# MSPM0G321X register map
Vendor: Texas Instruments; File version: Revised: 2025-10-06 10:58:04
CPU: CM0 r0p1, little endian, MPU, no FPU, 3 interrupt priority bits
Registers are 32-bit, read-write, reset 0x0 unless marked. A register's access mark holds for its fields unless they carry their own. Offsets are from the block's base; [hi:lo] are bit positions; lines under a group give offsets from that group; {n}, {i} and the like mark numbered series; 'fields as' and 'values as' point back to an identical list.

## SPG0 — PERIPHERALREGION
Base 0x40A9F000
{0x1120+4i} SPG0_UNICOMM_LPBK[{i}] (i=0..0) group
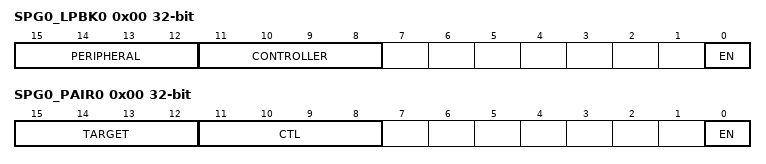
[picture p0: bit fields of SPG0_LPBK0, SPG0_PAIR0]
  0x00 SPG0_LPBK0 — Loopback between SPG instances User has to ensure that the SPGs looped back have the same underlying IP instantiated; i.e. both UART, both SPI, both I2C, etc.,
    [15:12] PERIPHERAL — Select SPG peripheral for loopback. Signals invovled in loopback based on interface chosen 1. SPI : CS, SCLK, SDI, SDO 2. I2C : SCL, SDA 3. UART : TX, RX
      {v}=SPG{v+1} (SPG responder select for loopback.) (v=0..15)
    [11:8] CONTROLLER — Select SPG controller for loopback. Signals invovled in loopback based on interface chosen 1. SPI : CS, SCLK, SDI, SDO 2. I2C : SCL, SDA 3. UART : TX, RX
      {v}=SPG{v+1} (SPG commander select for loopback.) (v=0..15)
    [0] EN — Loopback enable
      0=DISABLE (Does not select this clock as a source); 1=ENABLE (Select this clock as a source)
{0x11C0+4i} SPG0_I2C_PAIR[{i}] (i=0..0) group
  0x00 SPG0_PAIR0 — Pairing of I2C for MULTI-MASTER/SMBUS applications
    [15:12] TARGET — UNICOMM instance for loopback. This instance will be treated as the target
      {v}=SPG{v+1} (SPG responder select for loopback.) (v=0..15)
    [11:8] CTL — UNICOMM instance for loopback. This instance will be treated as the controller.
      {v}=SPG{v+1} (SPG commander select for loopback.) (v=0..15)
    [0] EN — Enable
      values as SPG0_UNICOMM_LPBK[0].SPG0_LPBK0.EN

## IOMUX — PERIPHERALREGION
Base 0x40428000
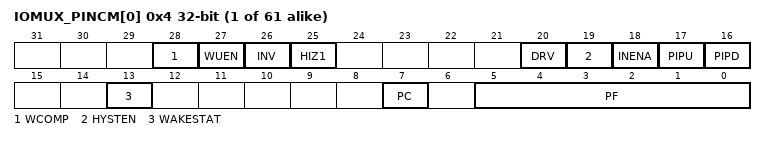
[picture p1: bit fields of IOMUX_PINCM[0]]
{0x4+4i} IOMUX_PINCM[{i}] (i=0..60) — Pin Control Management Register in SECCFG region
  [28] WCOMP — Wakeup Compare Value bit
    0=MATCH0 (Wakeup on a match of 0); 1=MATCH1 (Wakeup on a match of 1)
  [27] WUEN — Wakeup Enable bit
    0=DISABLE (wakeup is disabled.); 1=ENABLE (wakeup is enabled)
  [26] INV — Data inversion selection
    0=DISABLE (Data inversion is disabled.); 1=ENABLE (Data inversion is enabled)
  [25] HIZ1 — High output value will tri-state the output when this bit is enabled
    0=DISABLE (open-drain is disabled.); 1=ENABLE (open-drain is enabled.)
  [20] DRV — Drive strength control selection, for HS IOCELL only
    0=DRVVAL0 (Drive setting of 0 selected); 1=DRVVAL1 (Drive setting of 1 selected)
  [19] HYSTEN — Hysteresis Enable Control Selection
    0=DISABLE (hysteresis is disabled.); 1=ENABLE (hysteresis is enabled)
  [18] INENA — Input Enable Control Selection
    0=DISABLE (Input enable is disabled.); 1=ENABLE (Input enable is enabled.)
  [17] PIPU — Pull Up control selection
    0=DISABLE (Pull up is disabled.); 1=ENABLE (Pull up is enabled)
  [16] PIPD — Pull Down control selection
    0=DISABLE (Pull down is disabled.); 1=ENABLE (Pull down is enabled)
  [13] WAKESTAT ro — This has the IOPAD WAKEUP signal as status bit.
    0=DISABLE (wakeup source is NOT from this IOCELL); 1=ENABLE (wakeup source is from this IOCELL)
  [7] PC — Peripheral is Connected
    0=UNCONNECTED (The output of the peripheral (and its output enable) will not propagate to the IOCELL); 1=CONNECTED (The output latch of the dataflow will be transparent)
  [5:0] PF — Peripheral Function selection bits

## ADC0_SVT — PERIPHERALREGIONSVT
Base 0x4055A000
0x556160 ADC0_FIFODATA ro — FIFO Data Register
{0x556280+4i} ADC0_MEMRES[{i}] (i=0..11) ro — Memory Result Register
  [15:0] DATA — MEMRES result register. If DF = 0, unsigned binary: The conversion results are right aligned. In 10 and 8 bit modes, the unused MSB bits are forced to 0. If DF = 1, 2s-complement format: The conversion results are left aligned. In 10 and 8 bit modes, the unused LSB bits are forced to 0. The data is stored in the right-justified format and is converted to the left-justified 2s-complement format during read back.

## ADC1_SVT — PERIPHERALREGIONSVT
Base 0x4055C000
0x556160 ADC1_FIFODATA ro — FIFO Data Register
{0x556280+4i} ADC1_MEMRES[{i}] (i=0..11) ro — Memory Result Register
  [15:0] DATA — MEMRES result register. If DF = 0, unsigned binary: The conversion results are right aligned. In 10 and 8 bit modes, the unused MSB bits are forced to 0. If DF = 1, 2s-complement format: The conversion results are left aligned. In 10 and 8 bit modes, the unused LSB bits are forced to 0. The data is stored in the right-justified format and is converted to the left-justified 2s-complement format during read back.

## VREF — PERIPHERALREGION
Base 0x40030000
{0x800+0x18*i} VREF_GPRCM[{i}] (i=0..0) group
  0x00 VREF_PWREN — Power enable
    [0] ENABLE — Enable the power
      0=DISABLE (Disable Power); 1=ENABLE (Enable Power)
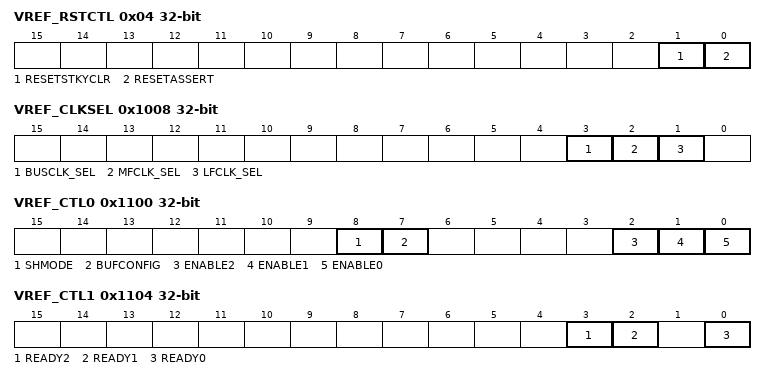
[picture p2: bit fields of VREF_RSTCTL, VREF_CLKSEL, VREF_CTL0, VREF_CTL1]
  0x04 VREF_RSTCTL wo — Reset Control
    [1] RESETSTKYCLR — Clear the RESETSTKY bit in the STAT register
      0=NOP (Writing 0 has no effect); 1=CLR (Clear reset sticky bit)
    [0] RESETASSERT — Assert reset to the peripheral
      0=NOP (Writing 0 has no effect); 1=ASSERT (Assert reset)
  0x14 VREF_STAT ro — Status Register
    [16] RESETSTKY — This bit indicates, if the peripheral was reset, since this bit was cleared by RESETSTKYCLR in the RSTCTL register
      0=NORES (The peripheral has not been reset since this bit was last cleared by RESETSTKYCLR in the RSTCTL register); 1=RESET (The peripheral was reset since the last bit clear)
0x1000 VREF_CLKDIV — Clock Divider
  [2:0] RATIO — Selects divide ratio of module clock to be used in sample and hold logic
0x1008 VREF_CLKSEL — Clock Selection
  [3] BUSCLK_SEL — Selects BUSCLK as clock source if enabled
  [2] MFCLK_SEL — Selects MFCLK as clock source if enabled
  [1] LFCLK_SEL — Selects LFCLK as clock source if enabled
0x1100 VREF_CTL0 — Control 0
  [8] SHMODE — This bit enable sample and hold mode
    0=DISABLE (Sample and hold mode is disable); 1=Enable (Sample and hold mode is enable)
  [7] BUFCONFIG — These bits configure output buffer.
    0=OUTPUT2P5V (Configure Output Buffer to 2.5v); 1=OUTPUT1P4V (Configure Output Buffer to 1.4v)
  [2] ENABLE2 — This bit enables the VREF2
    0=DISABLE (VREF2 is disabled); 1=ENABLE (VREF2 is enabled)
  [1] ENABLE1 — This bit enables the VREF1
    0=DISABLE (VREF1 is disabled); 1=ENABLE (VREF1 is enabled)
  [0] ENABLE0 — This bit enables the VREF0
    0=DISABLE (VREF0 is disabled); 1=ENABLE (VREF0 is enabled)
0x1104 VREF_CTL1 — Control 1
  [3] READY2 ro — These bits defines status of VREF2
    0=NOTRDY (VREF2 not Ready); 1=RDY (VREF2 Ready)
  [2] READY1 ro — These bits defines status of VREF1
    0=NOTRDY (VREF1 not Ready); 1=RDY (VREF1 ready)
  [0] READY0 ro — These bits defines status of VREF0
    0=NOTRDY (VREF0 not ready); 1=RDY (VREF ready)
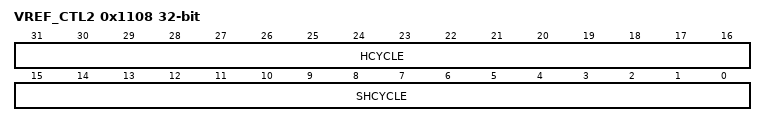
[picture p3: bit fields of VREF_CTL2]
0x1108 VREF_CTL2 — Control 2
  [31:16] HCYCLE — Hold cycle count Total cycles of module clock for hold phase when VREF is working in sample and hold mode in STANDBY to save power. Please refer VREF section of datasheet for recommended values of sample and hold times.
  [15:0] SHCYCLE — Sample and Hold cycle count Total cycles of module clock for sample and hold phase when VREF is working in sample and hold mode in STANDBY to save power. This field should be greater than HCYCLE field. The difference between this field and HCYCLE gives the number of cycles of sample phase. Please refer VREF section of datasheet for recommended values of sample and hold times.
